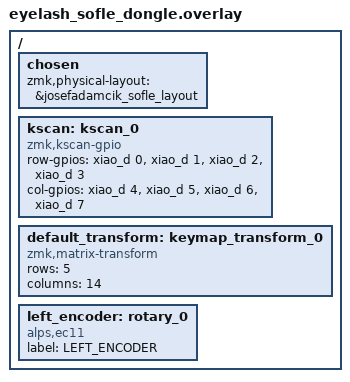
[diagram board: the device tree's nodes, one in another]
#include <dt-bindings/zmk/matrix_transform.h>
#include <layouts/josefadamcik/sofle.dtsi>
/ {
    chosen {
        zmk,physical-layout = &josefadamcik_sofle_layout;
    };

    // GPIO KScan für linke Hälfte
    kscan: kscan_0 {
        compatible = "zmk,kscan-gpio";
        row-gpios = <&xiao_d 0 GPIO_ACTIVE_HIGH>,
                    <&xiao_d 1 GPIO_ACTIVE_HIGH>,
                    <&xiao_d 2 GPIO_ACTIVE_HIGH>,
                    <&xiao_d 3 GPIO_ACTIVE_HIGH>;
        col-gpios = <&xiao_d 4 GPIO_ACTIVE_HIGH>,
                    <&xiao_d 5 GPIO_ACTIVE_HIGH>,
                    <&xiao_d 6 GPIO_ACTIVE_HIGH>,
                    <&xiao_d 7 GPIO_ACTIVE_HIGH>;
    };

    // Matrix Transform
    default_transform: keymap_transform_0 {
        compatible = "zmk,matrix-transform";
        rows = <5>;      // 0–4 aus JSON
        columns = <14>;  // 0–13 aus JSON
    };

    // Sensor / Encoder
    left_encoder: rotary_0 {
        compatible = "alps,ec11";
        label = "LEFT_ENCODER";
    };
};

